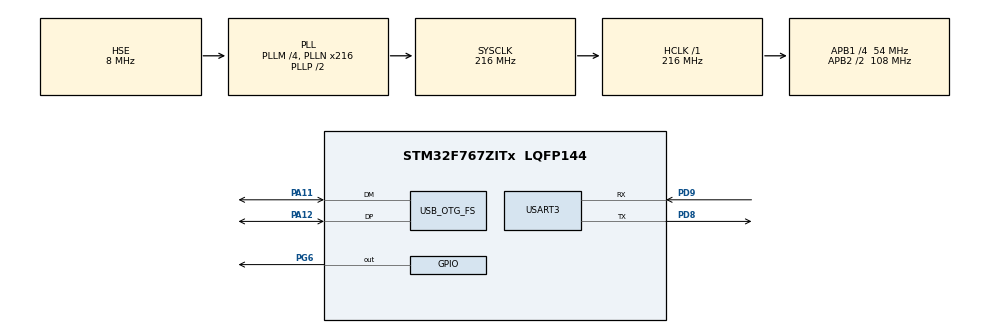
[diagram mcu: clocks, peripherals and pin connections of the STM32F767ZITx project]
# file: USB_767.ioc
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FATFS._MAX_SS=4096
Mcu.Family=STM32F7
Mcu.Name=STM32F767ZITx
Mcu.Package=LQFP144
NVIC.OTG_FS_IRQn=true\:0\:0\:false\:false\:true\:false\:true
NVIC.PriorityGroup=NVIC_PRIORITYGROUP_4
NVIC.TIM8_TRG_COM_TIM14_IRQn=true\:15\:0\:false\:false\:true\:false\:true
NVIC.TimeBase=TIM8_TRG_COM_TIM14_IRQn
NVIC.TimeBaseIP=TIM14
PA11.Mode=Host_Only
PA11.Signal=USB_OTG_FS_DM
PA12.Mode=Host_Only
PA12.Signal=USB_OTG_FS_DP
PA13.Mode=Trace_Asynchronous_SW
PA13.Signal=SYS_JTMS-SWDIO
PA14.Mode=Trace_Asynchronous_SW
PA14.Signal=SYS_JTCK-SWCLK
PB3.Mode=Trace_Asynchronous_SW
PB3.Signal=SYS_JTDO-SWO
PD8.Mode=Asynchronous
PD8.Signal=USART3_TX
PD9.Mode=Asynchronous
PD9.Signal=USART3_RX
PG6.Signal=GPIO_Output
PH0/OSC_IN.Mode=HSE-External-Oscillator
PH0/OSC_IN.Signal=RCC_OSC_IN
PH1/OSC_OUT.Mode=HSE-External-Oscillator
PH1/OSC_OUT.Signal=RCC_OSC_OUT
ProjectManager.HeapSize=0x200
ProjectManager.StackSize=0x400
ProjectManager.TargetToolchain=STM32CubeIDE
RCC.AHBFreq_Value=216000000
RCC.APB1CLKDivider=RCC_HCLK_DIV4
RCC.APB1Freq_Value=54000000
RCC.APB1TimFreq_Value=108000000
RCC.APB2CLKDivider=RCC_HCLK_DIV2
RCC.APB2Freq_Value=108000000
RCC.APB2TimFreq_Value=216000000
RCC.CortexFreq_Value=216000000
RCC.HCLKFreq_Value=216000000
RCC.HSE_VALUE=8000000
RCC.HSI_VALUE=16000000
RCC.LSE_VALUE=32768
RCC.PLLM=4
RCC.PLLN=216
RCC.PLLQ=9
RCC.SYSCLKFreq_VALUE=216000000
RCC.SYSCLKSource=RCC_SYSCLKSOURCE_PLLCLK
RCC.USBFreq_Value=48000000
RCC.VCOOutputFreq_Value=432000000
USART3.VirtualMode-Asynchronous=VM_ASYNC
USB_HOST.BSP.number=1
USB_HOST.USBH_HandleTypeDef-MSC_FS=hUsbHostFS
USB_HOST.VirtualModeFS=Msc
USB_HOST0.BSP.STBoard=false
USB_HOST0.BSP.api=Unknown
USB_HOST0.BSP.i2caddr=0
USB_HOST0.BSP.instance=PG6
USB_HOST0.BSP.ip=GPIO
USB_HOST0.BSP.mode=Output
USB_HOST0.BSP.name=Drive_VBUS_FS
USB_HOST0.BSP.solution=PG6
USB_OTG_FS.VirtualMode=Host_Only
USB_OTG_FS.phy_itface=HCD_PHY_EMBEDDED
VP_FATFS_VS_USB.Mode=USB
VP_SYS_VS_tim14.Mode=TIM14
VP_USB_HOST_VS_USB_HOST_MSC_FS.Mode=MSC_FS
board=custom

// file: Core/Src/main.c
/* USER CODE BEGIN Header */
/**
  ******************************************************************************
  * @file           : main.c
  * @brief          : Main program body
  ******************************************************************************
  * @attention
  *
  * Copyright (c) 2023 STMicroelectronics.
  * All rights reserved.
  *
  * This software is licensed under terms that can be found in the LICENSE file
  * in the root directory of this software component.
  * If no LICENSE file comes with this software, it is provided AS-IS.
  *
  ******************************************************************************
  */
/* USER CODE END Header */
#include "main.h"
#include "fatfs.h"
#include "usb_host.h"

/* USER CODE BEGIN Includes */
#include <stdio.h> /* для printf */
/* USER CODE END Includes */

UART_HandleTypeDef huart3;

void SystemClock_Config(void);
static void MX_GPIO_Init(void);
static void MX_USART3_UART_Init(void);
void MX_USB_HOST_Process(void);

/* USER CODE BEGIN 0 */
#ifdef __GNUC__
/* With GCC/RAISONANCE, small printf (option LD Linker->Libraries->Small printf
 set to 'Yes') calls __io_putchar() */
#define PUTCHAR_PROTOTYPE int __io_putchar(int ch)
#else
#define PUTCHAR_PROTOTYPE int fputc(int ch, FILE *f)
#endif /* __GNUC__ */
/* USER CODE END 0 */

int main(void)
{

  /* MCU Configuration--------------------------------------------------------*/

  /* Reset of all peripherals, Initializes the Flash interface and the Systick. */
  HAL_Init();

  /* Configure the system clock */
  SystemClock_Config();

  /* Initialize all configured peripherals */
  MX_GPIO_Init();
  MX_USART3_UART_Init();
  MX_FATFS_Init();
  MX_USB_HOST_Init();
  /* USER CODE BEGIN 2 */
  printf("Hello world! \r\n");
  /* USER CODE END 2 */

  /* Infinite loop */
  while (1)
  {
    MX_USB_HOST_Process();

  }
}

void SystemClock_Config(void)
{
  RCC_OscInitTypeDef RCC_OscInitStruct = {0};
  RCC_ClkInitTypeDef RCC_ClkInitStruct = {0};

  /** Configure the main internal regulator output voltage
  */
  __HAL_RCC_PWR_CLK_ENABLE();
  __HAL_PWR_VOLTAGESCALING_CONFIG(PWR_REGULATOR_VOLTAGE_SCALE1);
  /** Initializes the RCC Oscillators according to the specified parameters
  * in the RCC_OscInitTypeDef structure.
  */
  RCC_OscInitStruct.OscillatorType = RCC_OSCILLATORTYPE_HSE;
  RCC_OscInitStruct.HSEState = RCC_HSE_ON;
  RCC_OscInitStruct.PLL.PLLState = RCC_PLL_ON;
  RCC_OscInitStruct.PLL.PLLSource = RCC_PLLSOURCE_HSE;
  RCC_OscInitStruct.PLL.PLLM = 4;
  RCC_OscInitStruct.PLL.PLLN = 216;
  RCC_OscInitStruct.PLL.PLLP = RCC_PLLP_DIV2;
  RCC_OscInitStruct.PLL.PLLQ = 9;
  RCC_OscInitStruct.PLL.PLLR = 2;
  if (HAL_RCC_OscConfig(&RCC_OscInitStruct) != HAL_OK)
  {
    Error_Handler();
  }
  /** Activate the Over-Drive mode
  */
  if (HAL_PWREx_EnableOverDrive() != HAL_OK)
  {
    Error_Handler();
  }
  /** Initializes the CPU, AHB and APB buses clocks
  */
  RCC_ClkInitStruct.ClockType = RCC_CLOCKTYPE_HCLK|RCC_CLOCKTYPE_SYSCLK
                              |RCC_CLOCKTYPE_PCLK1|RCC_CLOCKTYPE_PCLK2;
  RCC_ClkInitStruct.SYSCLKSource = RCC_SYSCLKSOURCE_PLLCLK;
  RCC_ClkInitStruct.AHBCLKDivider = RCC_SYSCLK_DIV1;
  RCC_ClkInitStruct.APB1CLKDivider = RCC_HCLK_DIV4;
  RCC_ClkInitStruct.APB2CLKDivider = RCC_HCLK_DIV2;

  if (HAL_RCC_ClockConfig(&RCC_ClkInitStruct, FLASH_LATENCY_7) != HAL_OK)
  {
    Error_Handler();
  }
}

static void MX_USART3_UART_Init(void)
{

  huart3.Instance = USART3;
  huart3.Init.BaudRate = 115200;
  huart3.Init.WordLength = UART_WORDLENGTH_8B;
  huart3.Init.StopBits = UART_STOPBITS_1;
  huart3.Init.Parity = UART_PARITY_NONE;
  huart3.Init.Mode = UART_MODE_TX_RX;
  huart3.Init.HwFlowCtl = UART_HWCONTROL_NONE;
  huart3.Init.OverSampling = UART_OVERSAMPLING_16;
  huart3.Init.OneBitSampling = UART_ONE_BIT_SAMPLE_DISABLE;
  huart3.AdvancedInit.AdvFeatureInit = UART_ADVFEATURE_NO_INIT;
  if (HAL_UART_Init(&huart3) != HAL_OK)
  {
    Error_Handler();
  }

}

static void MX_GPIO_Init(void)
{
  GPIO_InitTypeDef GPIO_InitStruct = {0};

  /* GPIO Ports Clock Enable */
  __HAL_RCC_GPIOH_CLK_ENABLE();
  __HAL_RCC_GPIOD_CLK_ENABLE();
  __HAL_RCC_GPIOG_CLK_ENABLE();
  __HAL_RCC_GPIOA_CLK_ENABLE();
  __HAL_RCC_GPIOB_CLK_ENABLE();

  /*Configure GPIO pin Output Level */
  HAL_GPIO_WritePin(GPIOG, GPIO_PIN_6, GPIO_PIN_RESET);

  /*Configure GPIO pin : PG6 */
  GPIO_InitStruct.Pin = GPIO_PIN_6;
  GPIO_InitStruct.Mode = GPIO_MODE_OUTPUT_PP;
  GPIO_InitStruct.Pull = GPIO_NOPULL;
  GPIO_InitStruct.Speed = GPIO_SPEED_FREQ_LOW;
  HAL_GPIO_Init(GPIOG, &GPIO_InitStruct);

}

/* USER CODE BEGIN 4 */
/**
 * @brief Retargets the C library printf function to the USART.
 * @param None
 * @retval None
 */
PUTCHAR_PROTOTYPE
{
 /* Place your implementation of fputc here */
 /* e.g. write a character to the USART2 and Loop until the end of transmission */
 HAL_UART_Transmit(&huart3, (uint8_t *)&ch, 1, 0xFFFF);

return ch;
}
/* USER CODE END 4 */

void HAL_TIM_PeriodElapsedCallback(TIM_HandleTypeDef *htim)
{
  if (htim->Instance == TIM14) {
    HAL_IncTick();
  }
}

void Error_Handler(void)
{
  __disable_irq();
  while (1)
  {
  }
}
